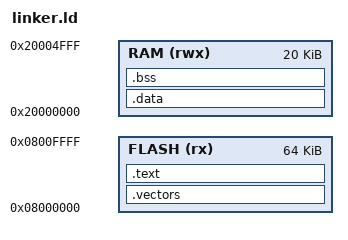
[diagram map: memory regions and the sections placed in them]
MEMORY
{
    FLASH (rx) : ORIGIN = 0x08000000, LENGTH = 64K
    RAM   (rwx): ORIGIN = 0x20000000, LENGTH = 20K
}

_stack_top = ORIGIN(RAM) + LENGTH(RAM);

SECTIONS
{
    .vectors :
    {
        KEEP(*(.vectors))
    } > FLASH

    .text :
    {
        *(.text*)
        *(.rodata*)
    } > FLASH

    . = ALIGN(4);
    _etext = .;

    .data : AT(_etext)
    {
        _sdata = .;
        *(.data*)
        . = ALIGN(4);
        _edata = .;
    } > RAM

    .bss :
    {
        _sbss = .;
        *(.bss*)
        *(COMMON)
        . = ALIGN(4);
        _ebss = .;
    } > RAM
}
